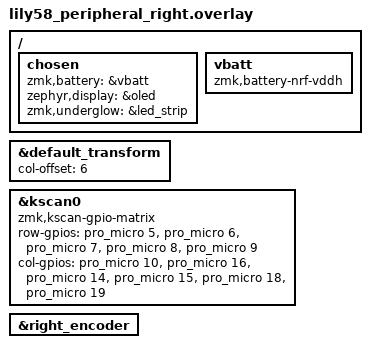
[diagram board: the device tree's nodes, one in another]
/*
 * Copyright (c) 2020 Pete Johanson
 *
 * SPDX-License-Identifier: MIT
 */

#include "lily58.dtsi"
#include <dt-bindings/led/led.h>
&default_transform {
    col-offset = <6>;
};

&kscan0 {
    compatible = "zmk,kscan-gpio-matrix";
    row-gpios
        = <&pro_micro 5 (GPIO_ACTIVE_HIGH | GPIO_PULL_DOWN)>
        , <&pro_micro 6 (GPIO_ACTIVE_HIGH | GPIO_PULL_DOWN)>
        , <&pro_micro 7 (GPIO_ACTIVE_HIGH | GPIO_PULL_DOWN)>
        , <&pro_micro 8 (GPIO_ACTIVE_HIGH | GPIO_PULL_DOWN)>
        , <&pro_micro 9 (GPIO_ACTIVE_HIGH | GPIO_PULL_DOWN)>
        ;
    col-gpios
        = <&pro_micro 10 GPIO_ACTIVE_HIGH>
        , <&pro_micro 16 GPIO_ACTIVE_HIGH>
        , <&pro_micro 14 GPIO_ACTIVE_HIGH>
        , <&pro_micro 15 GPIO_ACTIVE_HIGH>
        , <&pro_micro 18 GPIO_ACTIVE_HIGH>
        , <&pro_micro 19 GPIO_ACTIVE_HIGH>
        ;
};
&right_encoder {
    status = "okay";
};
/ {
    chosen {
      zmk,battery = &vbatt;
      zephyr,display = &oled;
      zmk,underglow = &led_strip;
    };

    vbatt: vbatt {
        compatible = "zmk,battery-nrf-vddh";
    };
};
